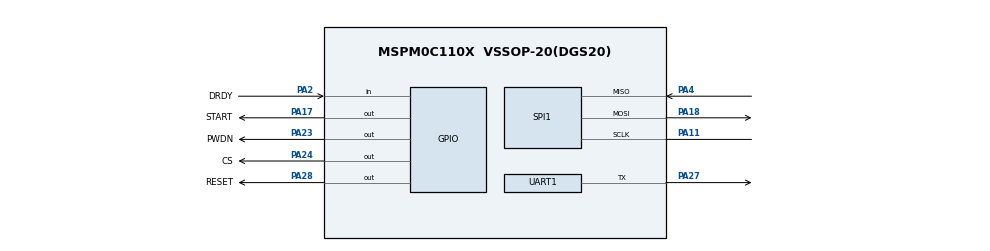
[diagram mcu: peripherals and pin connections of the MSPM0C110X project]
/**
 * @cliArgs --device "MSPM0C110X" --part "Default" --package "VSSOP-20(DGS20)" --product "mspm0_sdk@2.07.00.06"
 * @versions {"tool":"1.25.0+4268"}
 */

/**
 * Import the modules used in this configuration.
 */
const GPIO   = scripting.addModule("/ti/driverlib/GPIO", {}, false);
const GPIO1  = GPIO.addInstance();
const SPI    = scripting.addModule("/ti/driverlib/SPI", {}, false);
const SPI1   = SPI.addInstance();
const SYSCTL = scripting.addModule("/ti/driverlib/SYSCTL");
const UART   = scripting.addModule("/ti/driverlib/UART", {}, false);
const UART1  = UART.addInstance();

/**
 * Write custom configuration values to the imported modules.
 */
GPIO1.$name                               = "GPIO_A";
GPIO1.associatedPins.create(6);
GPIO1.associatedPins[0].initialValue      = "SET";
GPIO1.associatedPins[0].assignedPin       = "22";
GPIO1.associatedPins[0].$name             = "RED_22";
GPIO1.associatedPins[1].$name             = "CS";
GPIO1.associatedPins[1].ioStructure       = "SD";
GPIO1.associatedPins[1].initialValue      = "SET";
GPIO1.associatedPins[1].pin.$assign       = "PA24";
GPIO1.associatedPins[2].initialValue      = "SET";
GPIO1.associatedPins[2].direction         = "INPUT";
GPIO1.associatedPins[2].$name             = "DRDY";
GPIO1.associatedPins[2].interruptPriority = "1";
GPIO1.associatedPins[2].polarity          = "FALL";
GPIO1.associatedPins[2].pin.$assign       = "PA2";
GPIO1.associatedPins[3].$name             = "PWDN";
GPIO1.associatedPins[3].initialValue      = "SET";
GPIO1.associatedPins[3].pin.$assign       = "PA23";
GPIO1.associatedPins[4].$name             = "START";
GPIO1.associatedPins[4].pin.$assign       = "PA17";
GPIO1.associatedPins[5].$name             = "RESET";
GPIO1.associatedPins[5].initialValue      = "SET";
GPIO1.associatedPins[5].pin.$assign       = "PA28";

const Board = scripting.addModule("/ti/driverlib/Board", {}, false);

SPI1.$name                      = "SPI_0";
SPI1.phase                      = "1";
SPI1.chipSelect                 = [];
SPI1.frameFormat                = "MOTO3";
SPI1.targetBitRate              = 1000000;
SPI1.sclkPinConfig.$name        = "ti_driverlib_gpio_GPIOPinGeneric0";
SPI1.mosiPinConfig.$name        = "ti_driverlib_gpio_GPIOPinGeneric1";
SPI1.misoPinConfig.$name        = "ti_driverlib_gpio_GPIOPinGeneric2";
SPI1.peripheral.$assign         = "SPI0";
SPI1.peripheral.sclkPin.$assign = "PA11";
SPI1.peripheral.mosiPin.$assign = "PA18";
SPI1.peripheral.misoPin.$assign = "PA4";


UART1.$name                    = "UART_0";
UART1.direction                = "TX";
UART1.parity                   = "ODD";
UART1.targetBaudRate           = 1000000;
UART1.txPinConfig.$name        = "ti_driverlib_gpio_GPIOPinGeneric3";
UART1.peripheral.$assign       = "UART0";
UART1.peripheral.txPin.$assign = "PA27";

/**
 * Pinmux solution for unlocked pins/peripherals. This ensures that minor changes to the automatic solver in a future
 * version of the tool will not impact the pinmux you originally saw.  These lines can be completely deleted in order to
 * re-solve from scratch.
 */
GPIO1.associatedPins[0].pin.$suggestSolution = "PA22";
Board.peripheral.$suggestSolution            = "DEBUGSS";
Board.peripheral.swclkPin.$suggestSolution   = "PA20";
Board.peripheral.swdioPin.$suggestSolution   = "PA19";
SYSCTL.peripheral.$suggestSolution           = "SYSCTL";
